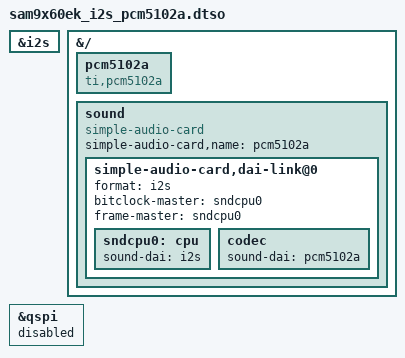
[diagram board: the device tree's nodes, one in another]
// SPDX-License-Identifier: (GPL-2.0+ OR MIT)
/*
 * sam9x60-ek_i2s_proto.dtso - Device Tree file for SAM9x60-EK board
 * overlay blob for I2S with PROTO board. The blob uses i2s0 and i2c2 on flx4.
 *
 * Copyright (C) 2019 Microchip Technology, Inc.
 * Author: Codrin Ciubotariu <codrin.ciubotariu@microchip.com>
 *
 */
/dts-v1/;
/plugin/;

&i2s {
	status = "okay";
};


&{/} {
	pcm5102a: pcm5102a {
		compatible = "ti,pcm5102a";
		#sound-dai-cells = <0>;
	};
	
	sound {
		compatible = "simple-audio-card";
		simple-audio-card,name= "pcm5102a";
		simple-audio-card,dai-link@0 {
			format = "i2s";
			bitclock-master = <&sndcpu0>;
			frame-master = <&sndcpu0>;
			
			sndcpu0: cpu {
				sound-dai = <&i2s>;
			};
			codec {
				sound-dai = <&pcm5102a>;
			};
		};
        };
};

&qspi {
	status = "disabled";
};

